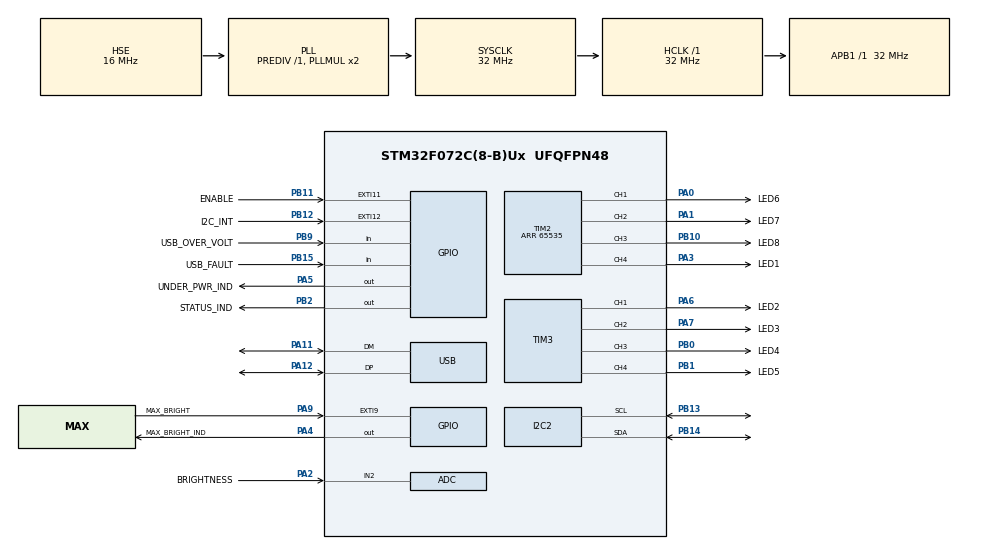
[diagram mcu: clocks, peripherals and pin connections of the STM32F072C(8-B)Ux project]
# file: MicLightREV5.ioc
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ADC.EOCSelection=ADC_EOC_SEQ_CONV
ADC.SamplingTime=ADC_SAMPLETIME_55CYCLES_5
I2C2.Timing=0x00707CBB
Mcu.Family=STM32F0
Mcu.Name=STM32F072C(8-B)Ux
Mcu.Package=UFQFPN48
NVIC.EXTI4_15_IRQn=true\:0\:0\:false\:false\:true\:true\:true\:true
NVIC.I2C2_IRQn=true\:0\:0\:false\:false\:true\:true\:true\:true
NVIC.TIM14_IRQn=true\:0\:0\:false\:false\:true\:true\:true\:true
NVIC.TIM15_IRQn=true\:0\:0\:false\:false\:true\:true\:true\:true
NVIC.TIM16_IRQn=true\:0\:0\:false\:false\:true\:true\:true\:true
NVIC.TIM7_IRQn=true\:0\:0\:false\:false\:true\:true\:true\:true
NVIC.USB_IRQn=true\:0\:0\:false\:false\:true\:true\:true\:true
PA0.GPIO_Label=LED6
PA0.Signal=S_TIM2_CH1_ETR
PA1.GPIO_Label=LED7
PA1.Signal=S_TIM2_CH2
PA11.Mode=Device
PA11.Signal=USB_DM
PA12.Mode=Device
PA12.Signal=USB_DP
PA13.Mode=Serial_Wire
PA13.Signal=SYS_SWDIO
PA14.Mode=Serial_Wire
PA14.Signal=SYS_SWCLK
PA2.GPIO_Label=BRIGHTNESS
PA2.Mode=IN2
PA2.Signal=ADC_IN2
PA3.GPIO_Label=LED1
PA3.Signal=S_TIM2_CH4
PA4.GPIO_Label=MAX_BRIGHT_IND
PA4.Signal=GPIO_Output
PA5.GPIO_Label=UNDER_PWR_IND
PA5.Signal=GPIO_Output
PA6.GPIO_Label=LED2
PA6.Signal=S_TIM3_CH1
PA7.GPIO_Label=LED3
PA7.Signal=S_TIM3_CH2
PA9.GPIO_Label=MAX_BRIGHT
PA9.Signal=GPXTI9
PB0.GPIO_Label=LED4
PB0.Signal=S_TIM3_CH3
PB1.GPIO_Label=LED5
PB1.Signal=S_TIM3_CH4
PB10.GPIO_Label=LED8
PB10.Signal=S_TIM2_CH3
PB11.GPIO_Label=ENABLE
PB11.GPIO_ModeDefaultEXTI=GPIO_MODE_IT_RISING
PB11.Signal=GPXTI11
PB12.GPIO_Label=I2C_INT
PB12.GPIO_ModeDefaultEXTI=GPIO_MODE_IT_FALLING
PB12.Signal=GPXTI12
PB13.Mode=I2C
PB13.Signal=I2C2_SCL
PB14.Mode=I2C
PB14.Signal=I2C2_SDA
PB15.GPIO_Label=USB_FAULT
PB15.Signal=GPIO_Input
PB2.GPIO_Label=STATUS_IND
PB2.Signal=GPIO_Output
PB9.GPIO_Label=USB_OVER_VOLT
PB9.Signal=GPIO_Input
PF0-OSC_IN.Mode=HSE-External-Oscillator
PF0-OSC_IN.Signal=RCC_OSC_IN
PF1-OSC_OUT.Mode=HSE-External-Oscillator
PF1-OSC_OUT.Signal=RCC_OSC_OUT
ProjectManager.HeapSize=0x400
ProjectManager.StackSize=0x400
ProjectManager.TargetToolchain=STM32CubeIDE
RCC.AHBFreq_Value=32000000
RCC.APB1Freq_Value=32000000
RCC.APB1TimFreq_Value=32000000
RCC.HCLKFreq_Value=32000000
RCC.HSE_VALUE=16000000
RCC.PLLSourceVirtual=RCC_PLLSOURCE_HSE
RCC.SYSCLKFreq_VALUE=32000000
RCC.SYSCLKSource=RCC_SYSCLKSOURCE_PLLCLK
SH.S_TIM2_CH1_ETR.0=TIM2_CH1,PWM Generation1 CH1
SH.S_TIM2_CH2.0=TIM2_CH2,PWM Generation2 CH2
SH.S_TIM2_CH3.0=TIM2_CH3,PWM Generation3 CH3
SH.S_TIM2_CH4.0=TIM2_CH4,PWM Generation4 CH4
SH.S_TIM3_CH1.0=TIM3_CH1,PWM Generation1 CH1
SH.S_TIM3_CH2.0=TIM3_CH2,PWM Generation2 CH2
SH.S_TIM3_CH3.0=TIM3_CH3,PWM Generation3 CH3
SH.S_TIM3_CH4.0=TIM3_CH4,PWM Generation4 CH4
TIM14.AutoReloadPreload=TIM_AUTORELOAD_PRELOAD_ENABLE
TIM14.Period=43680
TIM14.Prescaler=3662
TIM15.AutoReloadPreload=TIM_AUTORELOAD_PRELOAD_ENABLE
TIM15.Period=100
TIM15.TIM_MasterOutputTrigger=TIM_TRGO_UPDATE
TIM16.AutoReloadPreload=TIM_AUTORELOAD_PRELOAD_ENABLE
TIM16.Period=32000
TIM16.Prescaler=3
TIM2.AutoReloadPreload=TIM_AUTORELOAD_PRELOAD_ENABLE
TIM2.Channel-PWM\ Generation1\ CH1=TIM_CHANNEL_1
TIM2.Channel-PWM\ Generation2\ CH2=TIM_CHANNEL_2
TIM2.Channel-PWM\ Generation3\ CH3=TIM_CHANNEL_3
TIM2.Channel-PWM\ Generation4\ CH4=TIM_CHANNEL_4
TIM2.OCMode_PWM-PWM\ Generation2\ CH2=TIM_OCMODE_PWM2
TIM2.OCMode_PWM-PWM\ Generation4\ CH4=TIM_OCMODE_PWM2
TIM2.OCPolarity_2=TIM_OCPOLARITY_LOW
TIM2.OCPolarity_4=TIM_OCPOLARITY_LOW
TIM2.Period=65535
TIM3.AutoReloadPreload=TIM_AUTORELOAD_PRELOAD_ENABLE
TIM3.Channel-PWM\ Generation1\ CH1=TIM_CHANNEL_1
TIM3.Channel-PWM\ Generation2\ CH2=TIM_CHANNEL_2
TIM3.Channel-PWM\ Generation3\ CH3=TIM_CHANNEL_3
TIM3.Channel-PWM\ Generation4\ CH4=TIM_CHANNEL_4
TIM3.OCMode_PWM-PWM\ Generation2\ CH2=TIM_OCMODE_PWM2
TIM3.OCMode_PWM-PWM\ Generation4\ CH4=TIM_OCMODE_PWM2
TIM3.OCPolarity_2=TIM_OCPOLARITY_LOW
TIM3.OCPolarity_4=TIM_OCPOLARITY_LOW
TIM7.Period=43439
TIM7.Prescaler=220
TIM7.TIM_MasterOutputTrigger=TIM_TRGO_UPDATE
USB.lpm_enable=ENABLE
USB_DEVICE.CLASS_NAME_FS=CDC
USB_DEVICE.MANUFACTURER_STRING=DaxxnIndustries
USB_DEVICE.PRODUCT_STRING_CDC_FS=MicLight ComPort
USB_DEVICE.USBD_SELF_POWERED=0
USB_DEVICE.VirtualMode=Cdc
USB_DEVICE.VirtualModeFS=Cdc_FS
VP_ADC_TempSens_Input.Mode=IN-TempSens
VP_TIM14_VS_ClockSourceINT.Mode=Enable_Timer
VP_TIM15_VS_ClockSourceINT.Mode=Internal
VP_TIM16_VS_ClockSourceINT.Mode=Enable_Timer
VP_TIM2_VS_ClockSourceINT.Mode=Internal
VP_TIM3_VS_ClockSourceINT.Mode=Internal
VP_TIM7_VS_ClockSourceINT.Mode=Enable_Timer
VP_TIM7_VS_OPM.Mode=OPM_bit
VP_USB_DEVICE_VS_USB_DEVICE_CDC_FS.Mode=CDC_FS
board=custom

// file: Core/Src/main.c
/* USER CODE BEGIN Header */
/**
  ******************************************************************************
  * @file           : main.c
  * @brief          : Main program body
  ******************************************************************************
  * @attention
  *
  * Copyright (c) 2024 STMicroelectronics.
  * All rights reserved.
  *
  * This software is licensed under terms that can be found in the LICENSE file
  * in the root directory of this software component.
  * If no LICENSE file comes with this software, it is provided AS-IS.
  *
  ******************************************************************************
  */
/* USER CODE END Header */
#include "main.h"
#include "usb_device.h"

ADC_HandleTypeDef hadc;

I2C_HandleTypeDef hi2c2;

TIM_HandleTypeDef htim2;
TIM_HandleTypeDef htim3;
TIM_HandleTypeDef htim7;
TIM_HandleTypeDef htim14;
TIM_HandleTypeDef htim15;
TIM_HandleTypeDef htim16;

void SystemClock_Config(void);
static void MX_GPIO_Init(void);
static void MX_I2C2_Init(void);
static void MX_TIM2_Init(void);
static void MX_TIM3_Init(void);
static void MX_ADC_Init(void);
static void MX_TIM7_Init(void);
static void MX_TIM14_Init(void);
static void MX_TIM15_Init(void);
static void MX_TIM16_Init(void);

/* USER CODE BEGIN 0 */
void HAL_ADC_ConvCpltCallback(ADC_HandleTypeDef* hadc)
{
	ADCConvCallback();
}

void HAL_GPIO_EXTI_Callback(uint16_t GPIO_Pin)
{
	ExtInterruptCallback(GPIO_Pin);
}

void HAL_TIM_PeriodElapsedCallback(TIM_HandleTypeDef *htim)
{
	TimerElapsedCallback(htim);
}
/* USER CODE END 0 */

int main(void)
{

  /* MCU Configuration--------------------------------------------------------*/

  /* Reset of all peripherals, Initializes the Flash interface and the Systick. */
  HAL_Init();

  /* Configure the system clock */
  SystemClock_Config();

  /* Initialize all configured peripherals */
  MX_GPIO_Init();
  MX_I2C2_Init();
  MX_TIM2_Init();
  MX_TIM3_Init();
  MX_ADC_Init();
  MX_USB_DEVICE_Init();
  MX_TIM7_Init();
  MX_TIM14_Init();
  MX_TIM15_Init();
  MX_TIM16_Init();
  /* USER CODE BEGIN 2 */
  if (Init(&hadc, &htim2, &htim3, &htim7, &htim14, &htim15, &htim16, &hi2c2) != HAL_OK) {
	return HAL_ERROR;
  }
  /* USER CODE END 2 */

  /* Infinite loop */
  /* USER CODE BEGIN WHILE */
  while (1)
  {
	  Main();
    /* USER CODE END WHILE */

  }
}

void SystemClock_Config(void)
{
  RCC_OscInitTypeDef RCC_OscInitStruct = {0};
  RCC_ClkInitTypeDef RCC_ClkInitStruct = {0};
  RCC_PeriphCLKInitTypeDef PeriphClkInit = {0};

  /** Initializes the RCC Oscillators according to the specified parameters
  * in the RCC_OscInitTypeDef structure.
  */
  RCC_OscInitStruct.OscillatorType = RCC_OSCILLATORTYPE_HSI14|RCC_OSCILLATORTYPE_HSI48
                              |RCC_OSCILLATORTYPE_HSE;
  RCC_OscInitStruct.HSEState = RCC_HSE_ON;
  RCC_OscInitStruct.HSI48State = RCC_HSI48_ON;
  RCC_OscInitStruct.HSI14State = RCC_HSI14_ON;
  RCC_OscInitStruct.HSI14CalibrationValue = 16;
  RCC_OscInitStruct.PLL.PLLState = RCC_PLL_ON;
  RCC_OscInitStruct.PLL.PLLSource = RCC_PLLSOURCE_HSE;
  RCC_OscInitStruct.PLL.PLLMUL = RCC_PLL_MUL2;
  RCC_OscInitStruct.PLL.PREDIV = RCC_PREDIV_DIV1;
  if (HAL_RCC_OscConfig(&RCC_OscInitStruct) != HAL_OK)
  {
    Error_Handler();
  }

  /** Initializes the CPU, AHB and APB buses clocks
  */
  RCC_ClkInitStruct.ClockType = RCC_CLOCKTYPE_HCLK|RCC_CLOCKTYPE_SYSCLK
                              |RCC_CLOCKTYPE_PCLK1;
  RCC_ClkInitStruct.SYSCLKSource = RCC_SYSCLKSOURCE_PLLCLK;
  RCC_ClkInitStruct.AHBCLKDivider = RCC_SYSCLK_DIV1;
  RCC_ClkInitStruct.APB1CLKDivider = RCC_HCLK_DIV1;

  if (HAL_RCC_ClockConfig(&RCC_ClkInitStruct, FLASH_LATENCY_1) != HAL_OK)
  {
    Error_Handler();
  }
  PeriphClkInit.PeriphClockSelection = RCC_PERIPHCLK_USB;
  PeriphClkInit.UsbClockSelection = RCC_USBCLKSOURCE_HSI48;

  if (HAL_RCCEx_PeriphCLKConfig(&PeriphClkInit) != HAL_OK)
  {
    Error_Handler();
  }
}

static void MX_ADC_Init(void)
{

  ADC_ChannelConfTypeDef sConfig = {0};

  /** Configure the global features of the ADC (Clock, Resolution, Data Alignment and number of conversion)
  */
  hadc.Instance = ADC1;
  hadc.Init.ClockPrescaler = ADC_CLOCK_ASYNC_DIV1;
  hadc.Init.Resolution = ADC_RESOLUTION_12B;
  hadc.Init.DataAlign = ADC_DATAALIGN_RIGHT;
  hadc.Init.ScanConvMode = ADC_SCAN_DIRECTION_FORWARD;
  hadc.Init.EOCSelection = ADC_EOC_SEQ_CONV;
  hadc.Init.LowPowerAutoWait = DISABLE;
  hadc.Init.LowPowerAutoPowerOff = DISABLE;
  hadc.Init.ContinuousConvMode = DISABLE;
  hadc.Init.DiscontinuousConvMode = DISABLE;
  hadc.Init.ExternalTrigConv = ADC_SOFTWARE_START;
  hadc.Init.ExternalTrigConvEdge = ADC_EXTERNALTRIGCONVEDGE_NONE;
  hadc.Init.DMAContinuousRequests = DISABLE;
  hadc.Init.Overrun = ADC_OVR_DATA_PRESERVED;
  if (HAL_ADC_Init(&hadc) != HAL_OK)
  {
    Error_Handler();
  }

  /** Configure for the selected ADC regular channel to be converted.
  */
  sConfig.Channel = ADC_CHANNEL_2;
  sConfig.Rank = ADC_RANK_CHANNEL_NUMBER;
  sConfig.SamplingTime = ADC_SAMPLETIME_55CYCLES_5;
  if (HAL_ADC_ConfigChannel(&hadc, &sConfig) != HAL_OK)
  {
    Error_Handler();
  }

  /** Configure for the selected ADC regular channel to be converted.
  */
  sConfig.Channel = ADC_CHANNEL_TEMPSENSOR;
  if (HAL_ADC_ConfigChannel(&hadc, &sConfig) != HAL_OK)
  {
    Error_Handler();
  }

}

static void MX_I2C2_Init(void)
{

  hi2c2.Instance = I2C2;
  hi2c2.Init.Timing = 0x00707CBB;
  hi2c2.Init.OwnAddress1 = 0;
  hi2c2.Init.AddressingMode = I2C_ADDRESSINGMODE_7BIT;
  hi2c2.Init.DualAddressMode = I2C_DUALADDRESS_DISABLE;
  hi2c2.Init.OwnAddress2 = 0;
  hi2c2.Init.OwnAddress2Masks = I2C_OA2_NOMASK;
  hi2c2.Init.GeneralCallMode = I2C_GENERALCALL_DISABLE;
  hi2c2.Init.NoStretchMode = I2C_NOSTRETCH_DISABLE;
  if (HAL_I2C_Init(&hi2c2) != HAL_OK)
  {
    Error_Handler();
  }

  /** Configure Analogue filter
  */
  if (HAL_I2CEx_ConfigAnalogFilter(&hi2c2, I2C_ANALOGFILTER_ENABLE) != HAL_OK)
  {
    Error_Handler();
  }

  /** Configure Digital filter
  */
  if (HAL_I2CEx_ConfigDigitalFilter(&hi2c2, 0) != HAL_OK)
  {
    Error_Handler();
  }

}

static void MX_TIM2_Init(void)
{

  TIM_ClockConfigTypeDef sClockSourceConfig = {0};
  TIM_MasterConfigTypeDef sMasterConfig = {0};
  TIM_OC_InitTypeDef sConfigOC = {0};

  htim2.Instance = TIM2;
  htim2.Init.Prescaler = 0;
  htim2.Init.CounterMode = TIM_COUNTERMODE_UP;
  htim2.Init.Period = 65535;
  htim2.Init.ClockDivision = TIM_CLOCKDIVISION_DIV1;
  htim2.Init.AutoReloadPreload = TIM_AUTORELOAD_PRELOAD_ENABLE;
  if (HAL_TIM_Base_Init(&htim2) != HAL_OK)
  {
    Error_Handler();
  }
  sClockSourceConfig.ClockSource = TIM_CLOCKSOURCE_INTERNAL;
  if (HAL_TIM_ConfigClockSource(&htim2, &sClockSourceConfig) != HAL_OK)
  {
    Error_Handler();
  }
  if (HAL_TIM_PWM_Init(&htim2) != HAL_OK)
  {
    Error_Handler();
  }
  sMasterConfig.MasterOutputTrigger = TIM_TRGO_RESET;
  sMasterConfig.MasterSlaveMode = TIM_MASTERSLAVEMODE_DISABLE;
  if (HAL_TIMEx_MasterConfigSynchronization(&htim2, &sMasterConfig) != HAL_OK)
  {
    Error_Handler();
  }
  sConfigOC.OCMode = TIM_OCMODE_PWM1;
  sConfigOC.Pulse = 0;
  sConfigOC.OCPolarity = TIM_OCPOLARITY_HIGH;
  sConfigOC.OCFastMode = TIM_OCFAST_DISABLE;
  if (HAL_TIM_PWM_ConfigChannel(&htim2, &sConfigOC, TIM_CHANNEL_1) != HAL_OK)
  {
    Error_Handler();
  }
  sConfigOC.OCMode = TIM_OCMODE_PWM2;
  sConfigOC.OCPolarity = TIM_OCPOLARITY_LOW;
  if (HAL_TIM_PWM_ConfigChannel(&htim2, &sConfigOC, TIM_CHANNEL_2) != HAL_OK)
  {
    Error_Handler();
  }
  sConfigOC.OCMode = TIM_OCMODE_PWM1;
  sConfigOC.OCPolarity = TIM_OCPOLARITY_HIGH;
  if (HAL_TIM_PWM_ConfigChannel(&htim2, &sConfigOC, TIM_CHANNEL_3) != HAL_OK)
  {
    Error_Handler();
  }
  sConfigOC.OCMode = TIM_OCMODE_PWM2;
  sConfigOC.OCPolarity = TIM_OCPOLARITY_LOW;
  if (HAL_TIM_PWM_ConfigChannel(&htim2, &sConfigOC, TIM_CHANNEL_4) != HAL_OK)
  {
    Error_Handler();
  }
  HAL_TIM_MspPostInit(&htim2);

}

static void MX_TIM3_Init(void)
{

  TIM_ClockConfigTypeDef sClockSourceConfig = {0};
  TIM_MasterConfigTypeDef sMasterConfig = {0};
  TIM_OC_InitTypeDef sConfigOC = {0};

  htim3.Instance = TIM3;
  htim3.Init.Prescaler = 0;
  htim3.Init.CounterMode = TIM_COUNTERMODE_UP;
  htim3.Init.Period = 65535;
  htim3.Init.ClockDivision = TIM_CLOCKDIVISION_DIV1;
  htim3.Init.AutoReloadPreload = TIM_AUTORELOAD_PRELOAD_ENABLE;
  if (HAL_TIM_Base_Init(&htim3) != HAL_OK)
  {
    Error_Handler();
  }
  sClockSourceConfig.ClockSource = TIM_CLOCKSOURCE_INTERNAL;
  if (HAL_TIM_ConfigClockSource(&htim3, &sClockSourceConfig) != HAL_OK)
  {
    Error_Handler();
  }
  if (HAL_TIM_PWM_Init(&htim3) != HAL_OK)
  {
    Error_Handler();
  }
  sMasterConfig.MasterOutputTrigger = TIM_TRGO_RESET;
  sMasterConfig.MasterSlaveMode = TIM_MASTERSLAVEMODE_DISABLE;
  if (HAL_TIMEx_MasterConfigSynchronization(&htim3, &sMasterConfig) != HAL_OK)
  {
    Error_Handler();
  }
  sConfigOC.OCMode = TIM_OCMODE_PWM1;
  sConfigOC.Pulse = 0;
  sConfigOC.OCPolarity = TIM_OCPOLARITY_HIGH;
  sConfigOC.OCFastMode = TIM_OCFAST_DISABLE;
  if (HAL_TIM_PWM_ConfigChannel(&htim3, &sConfigOC, TIM_CHANNEL_1) != HAL_OK)
  {
    Error_Handler();
  }
  sConfigOC.OCMode = TIM_OCMODE_PWM2;
  sConfigOC.OCPolarity = TIM_OCPOLARITY_LOW;
  if (HAL_TIM_PWM_ConfigChannel(&htim3, &sConfigOC, TIM_CHANNEL_2) != HAL_OK)
  {
    Error_Handler();
  }
  sConfigOC.OCMode = TIM_OCMODE_PWM1;
  sConfigOC.OCPolarity = TIM_OCPOLARITY_HIGH;
  if (HAL_TIM_PWM_ConfigChannel(&htim3, &sConfigOC, TIM_CHANNEL_3) != HAL_OK)
  {
    Error_Handler();
  }
  sConfigOC.OCMode = TIM_OCMODE_PWM2;
  sConfigOC.OCPolarity = TIM_OCPOLARITY_LOW;
  if (HAL_TIM_PWM_ConfigChannel(&htim3, &sConfigOC, TIM_CHANNEL_4) != HAL_OK)
  {
    Error_Handler();
  }
  HAL_TIM_MspPostInit(&htim3);

}

static void MX_TIM7_Init(void)
{

  TIM_MasterConfigTypeDef sMasterConfig = {0};

  htim7.Instance = TIM7;
  htim7.Init.Prescaler = 220;
  htim7.Init.CounterMode = TIM_COUNTERMODE_UP;
  htim7.Init.Period = 43439;
  htim7.Init.AutoReloadPreload = TIM_AUTORELOAD_PRELOAD_DISABLE;
  if (HAL_TIM_Base_Init(&htim7) != HAL_OK)
  {
    Error_Handler();
  }
  if (HAL_TIM_OnePulse_Init(&htim7, TIM_OPMODE_SINGLE) != HAL_OK)
  {
    Error_Handler();
  }
  sMasterConfig.MasterOutputTrigger = TIM_TRGO_UPDATE;
  sMasterConfig.MasterSlaveMode = TIM_MASTERSLAVEMODE_DISABLE;
  if (HAL_TIMEx_MasterConfigSynchronization(&htim7, &sMasterConfig) != HAL_OK)
  {
    Error_Handler();
  }

}

static void MX_TIM14_Init(void)
{

  htim14.Instance = TIM14;
  htim14.Init.Prescaler = 3662;
  htim14.Init.CounterMode = TIM_COUNTERMODE_UP;
  htim14.Init.Period = 43680;
  htim14.Init.ClockDivision = TIM_CLOCKDIVISION_DIV1;
  htim14.Init.AutoReloadPreload = TIM_AUTORELOAD_PRELOAD_ENABLE;
  if (HAL_TIM_Base_Init(&htim14) != HAL_OK)
  {
    Error_Handler();
  }

}

static void MX_TIM15_Init(void)
{

  TIM_ClockConfigTypeDef sClockSourceConfig = {0};
  TIM_MasterConfigTypeDef sMasterConfig = {0};

  htim15.Instance = TIM15;
  htim15.Init.Prescaler = 0;
  htim15.Init.CounterMode = TIM_COUNTERMODE_UP;
  htim15.Init.Period = 100;
  htim15.Init.ClockDivision = TIM_CLOCKDIVISION_DIV1;
  htim15.Init.RepetitionCounter = 0;
  htim15.Init.AutoReloadPreload = TIM_AUTORELOAD_PRELOAD_ENABLE;
  if (HAL_TIM_Base_Init(&htim15) != HAL_OK)
  {
    Error_Handler();
  }
  sClockSourceConfig.ClockSource = TIM_CLOCKSOURCE_INTERNAL;
  if (HAL_TIM_ConfigClockSource(&htim15, &sClockSourceConfig) != HAL_OK)
  {
    Error_Handler();
  }
  sMasterConfig.MasterOutputTrigger = TIM_TRGO_UPDATE;
  sMasterConfig.MasterSlaveMode = TIM_MASTERSLAVEMODE_DISABLE;
  if (HAL_TIMEx_MasterConfigSynchronization(&htim15, &sMasterConfig) != HAL_OK)
  {
    Error_Handler();
  }

}

static void MX_TIM16_Init(void)
{

  htim16.Instance = TIM16;
  htim16.Init.Prescaler = 3;
  htim16.Init.CounterMode = TIM_COUNTERMODE_UP;
  htim16.Init.Period = 32000;
  htim16.Init.ClockDivision = TIM_CLOCKDIVISION_DIV1;
  htim16.Init.RepetitionCounter = 0;
  htim16.Init.AutoReloadPreload = TIM_AUTORELOAD_PRELOAD_ENABLE;
  if (HAL_TIM_Base_Init(&htim16) != HAL_OK)
  {
    Error_Handler();
  }

}

static void MX_GPIO_Init(void)
{
  GPIO_InitTypeDef GPIO_InitStruct = {0};

  /* GPIO Ports Clock Enable */
  __HAL_RCC_GPIOF_CLK_ENABLE();
  __HAL_RCC_GPIOA_CLK_ENABLE();
  __HAL_RCC_GPIOB_CLK_ENABLE();

  /*Configure GPIO pin Output Level */
  HAL_GPIO_WritePin(GPIOA, MAX_BRIGHT_IND_Pin|UNDER_PWR_IND_Pin, GPIO_PIN_RESET);

  /*Configure GPIO pin Output Level */
  HAL_GPIO_WritePin(STATUS_IND_GPIO_Port, STATUS_IND_Pin, GPIO_PIN_RESET);

  /*Configure GPIO pins : MAX_BRIGHT_IND_Pin UNDER_PWR_IND_Pin */
  GPIO_InitStruct.Pin = MAX_BRIGHT_IND_Pin|UNDER_PWR_IND_Pin;
  GPIO_InitStruct.Mode = GPIO_MODE_OUTPUT_PP;
  GPIO_InitStruct.Pull = GPIO_NOPULL;
  GPIO_InitStruct.Speed = GPIO_SPEED_FREQ_LOW;
  HAL_GPIO_Init(GPIOA, &GPIO_InitStruct);

  /*Configure GPIO pin : STATUS_IND_Pin */
  GPIO_InitStruct.Pin = STATUS_IND_Pin;
  GPIO_InitStruct.Mode = GPIO_MODE_OUTPUT_PP;
  GPIO_InitStruct.Pull = GPIO_NOPULL;
  GPIO_InitStruct.Speed = GPIO_SPEED_FREQ_LOW;
  HAL_GPIO_Init(STATUS_IND_GPIO_Port, &GPIO_InitStruct);

  /*Configure GPIO pin : ENABLE_Pin */
  GPIO_InitStruct.Pin = ENABLE_Pin;
  GPIO_InitStruct.Mode = GPIO_MODE_IT_RISING;
  GPIO_InitStruct.Pull = GPIO_NOPULL;
  HAL_GPIO_Init(ENABLE_GPIO_Port, &GPIO_InitStruct);

  /*Configure GPIO pin : I2C_INT_Pin */
  GPIO_InitStruct.Pin = I2C_INT_Pin;
  GPIO_InitStruct.Mode = GPIO_MODE_IT_FALLING;
  GPIO_InitStruct.Pull = GPIO_NOPULL;
  HAL_GPIO_Init(I2C_INT_GPIO_Port, &GPIO_InitStruct);

  /*Configure GPIO pins : USB_FAULT_Pin USB_OVER_VOLT_Pin */
  GPIO_InitStruct.Pin = USB_FAULT_Pin|USB_OVER_VOLT_Pin;
  GPIO_InitStruct.Mode = GPIO_MODE_INPUT;
  GPIO_InitStruct.Pull = GPIO_NOPULL;
  HAL_GPIO_Init(GPIOB, &GPIO_InitStruct);

  /*Configure GPIO pin : MAX_BRIGHT_Pin */
  GPIO_InitStruct.Pin = MAX_BRIGHT_Pin;
  GPIO_InitStruct.Mode = GPIO_MODE_IT_RISING;
  GPIO_InitStruct.Pull = GPIO_NOPULL;
  HAL_GPIO_Init(MAX_BRIGHT_GPIO_Port, &GPIO_InitStruct);

  /* EXTI interrupt init*/
  HAL_NVIC_SetPriority(EXTI4_15_IRQn, 0, 0);
  HAL_NVIC_EnableIRQ(EXTI4_15_IRQn);

}

void Error_Handler(void)
{
  __disable_irq();
  while (1)
  {
  }
}
